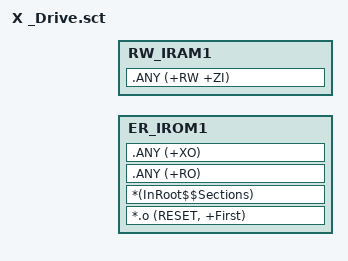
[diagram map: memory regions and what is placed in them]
#! armcc -E

; *************************************************************
; *** Scatter-Loading Description File generated by uVision ***
; *************************************************************

#include "stockpile_config.h"

LR_IROM1	STOCKPILE_APP_FIRMWARE_ADDR		STOCKPILE_APP_FIRMWARE_SIZE  {    ; load region size_region
  ER_IROM1	STOCKPILE_APP_FIRMWARE_ADDR		STOCKPILE_APP_FIRMWARE_SIZE  {  ; load address = execution address
   *.o (RESET, +First)
   *(InRoot$$Sections)
   .ANY (+RO)
   .ANY (+XO)
  }
  RW_IRAM1	STOCKPILE_RAM_APP_START		STOCKPILE_RAM_APP_SIZE  {  ; RW data
   .ANY (+RW +ZI)
  }
}
